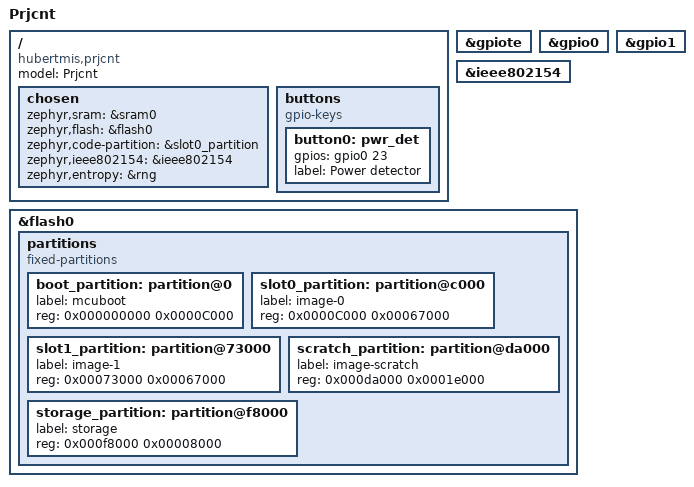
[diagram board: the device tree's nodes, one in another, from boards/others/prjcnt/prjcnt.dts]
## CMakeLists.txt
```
# Find Zephyr. This also loads Zephyr's build system.
cmake_minimum_required(VERSION 3.13.1)

set(CONF_FILE "prj.conf")
list(APPEND CONF_FILE "../config/openthread.conf")
list(APPEND CONF_FILE "../config/coap.conf")
list(APPEND CONF_FILE "../config/fota.conf")
list(APPEND CONF_FILE "../config/dfu.conf")

list(APPEND BOARD_ROOT ${CMAKE_CURRENT_SOURCE_DIR})
find_package(Zephyr REQUIRED HINTS $ENV{ZEPHYR_BASE})
project(rgbw)

# Add your source file to the "app" target. This must come after
# find_package(Zephyr) which defines the target.
target_sources(app PRIVATE src/coap.c)
target_sources(app PRIVATE src/main.c)
target_sources(app PRIVATE src/notification.c)
target_sources(app PRIVATE src/prov.c)
target_sources(app PRIVATE src/pwr_det.c)

# TODO: Replace with library target
target_include_directories(app PRIVATE ../lib)
target_sources(app PRIVATE ../lib/cbor_utils.c)
target_sources(app PRIVATE ../lib/coap_fota.c)
target_sources(app PRIVATE ../lib/coap_sd.c)
target_sources(app PRIVATE ../lib/coap_server.c)
target_sources(app PRIVATE ../lib/continuous_sd.c)
target_sources(app PRIVATE ../lib/ot_sed.c)

zephyr_get(COAPS_PSK SYSBUILD GLOBAL)
if(COAPS_PSK)
    target_compile_definitions(app PRIVATE
        -DCOAPS_PSK=${COAPS_PSK}
        )
else()
    message(FATAL_ERROR "Missing COAPS_PSK")
endif()
```

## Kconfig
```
# SPDX-License-Identifier: Apache-2.0

mainmenu "Temperature touchscreen menu"

source "Kconfig.zephyr"

config PRJCNT_NUM_NTF_SINKS
  int "prjcnt notification sinks number"
  default 6
  help
    Number of notification sinks for the projector controller application

config COAP_SD_MAX_NUM_RSRCS
  int "CoAP SD max resources"
  default PRJCNT_NUM_NTF_SINKS
  help
    Number of resources simultaneously being discovered by CoAP SD library

config CONTINUOUS_SD_MAX_NUM_RSRCS
  int "Continuous SD max resources"
  default PRJCNT_NUM_NTF_SINKS
  help
    Number of resources simultaneously being tracked by continuous SD library
```

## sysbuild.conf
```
SB_CONFIG_BOOTLOADER_MCUBOOT=y
SB_CONFIG_BOOT_SIGNATURE_TYPE_ECDSA_P256=y
```

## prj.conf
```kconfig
CONFIG_NEWLIB_LIBC=y
CONFIG_FPU=y
CONFIG_FPU_SHARING=y

CONFIG_MAIN_STACK_SIZE=3072
CONFIG_HEAP_MEM_POOL_SIZE=2048

CONFIG_FLASH=y

CONFIG_OPENTHREAD_MTD=y
CONFIG_OPENTHREAD_MTD_SED=y

CONFIG_MCUBOOT_IMGTOOL_SIGN_VERSION="0.2.0+0"

CONFIG_PRJCNT_NUM_NTF_SINKS=5
CONFIG_POSIX_MAX_FDS=16
CONFIG_NET_MAX_CONTEXTS=16
CONFIG_NET_MAX_CONN=16

CONFIG_RESET_ON_FATAL_ERROR=n
```

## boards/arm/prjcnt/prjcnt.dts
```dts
/*
 * Copyright (c) 2022 Hubert Miś
 *
 * SPDX-License-Identifier: Apache-2.0
 */

/dts-v1/;
#include <nordic/nrf52840_qiaa.dtsi>

/ {
	model = "Prjcnt";
	compatible = "hubertmis,prjcnt";

	chosen {
		zephyr,sram = &sram0;
		zephyr,flash = &flash0;
		zephyr,code-partition = &slot0_partition;
	};

    buttons {
        compatible = "gpio-keys";
        button0: pwr_det {
            gpios = <&gpio0 23 (GPIO_ACTIVE_HIGH)>;
            label = "Power detector";
        };
    };

    /*
    * In some default configurations within the nRF Connect SDK,
    * e.g. on nRF52840, the chosen zephyr,entropy node is &cryptocell.
    * This devicetree overlay ensures that default is overridden wherever it
    * is set, as this application uses the RNG node for entropy exclusively.
    */
    chosen {
        zephyr,entropy = &rng;
    };
};

&gpiote {
	status = "okay";
};

&gpio0 {
	status = "okay";
};

&gpio1 {
	status = "okay";
};

&flash0 {

	partitions {
		compatible = "fixed-partitions";
		#address-cells = <1>;
		#size-cells = <1>;

		boot_partition: partition@0 {
			label = "mcuboot";
			reg = <0x000000000 0x0000C000>;
		};
		slot0_partition: partition@c000 {
			label = "image-0";
			reg = <0x0000C000 0x00067000>;
		};
		slot1_partition: partition@73000 {
			label = "image-1";
			reg = <0x00073000 0x00067000>;
		};
		scratch_partition: partition@da000 {
			label = "image-scratch";
			reg = <0x000da000 0x0001e000>;
		};

		/*
		 * The flash starting at 0x000f8000 and ending at
		 * 0x000fffff is reserved for use by the application.
		 */

		/*
		 * Storage partition will be used by FCB/LittleFS/NVS
		 * if enabled.
		 */
		storage_partition: partition@f8000 {
			label = "storage";
			reg = <0x000f8000 0x00008000>;
		};
	};
};
```

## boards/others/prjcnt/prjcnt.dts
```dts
/*
 * Copyright (c) 2022 Hubert Miś
 *
 * SPDX-License-Identifier: Apache-2.0
 */

/dts-v1/;
#include <nordic/nrf52840_qiaa.dtsi>

/ {
	model = "Prjcnt";
	compatible = "hubertmis,prjcnt";

	chosen {
		zephyr,sram = &sram0;
		zephyr,flash = &flash0;
		zephyr,code-partition = &slot0_partition;
		zephyr,ieee802154 = &ieee802154;
	};

    buttons {
        compatible = "gpio-keys";
        button0: pwr_det {
            gpios = <&gpio0 23 (GPIO_ACTIVE_HIGH)>;
            label = "Power detector";
        };
    };

    /*
    * In some default configurations within the nRF Connect SDK,
    * e.g. on nRF52840, the chosen zephyr,entropy node is &cryptocell.
    * This devicetree overlay ensures that default is overridden wherever it
    * is set, as this application uses the RNG node for entropy exclusively.
    */
    chosen {
        zephyr,entropy = &rng;
    };
};

&gpiote {
	status = "okay";
};

&gpio0 {
	status = "okay";
};

&gpio1 {
	status = "okay";
};

&ieee802154 {
	status = "okay";
};

&flash0 {

	partitions {
		compatible = "fixed-partitions";
		#address-cells = <1>;
		#size-cells = <1>;

		boot_partition: partition@0 {
			label = "mcuboot";
			reg = <0x000000000 0x0000C000>;
		};
		slot0_partition: partition@c000 {
			label = "image-0";
			reg = <0x0000C000 0x00067000>;
		};
		slot1_partition: partition@73000 {
			label = "image-1";
			reg = <0x00073000 0x00067000>;
		};
		scratch_partition: partition@da000 {
			label = "image-scratch";
			reg = <0x000da000 0x0001e000>;
		};

		/*
		 * The flash starting at 0x000f8000 and ending at
		 * 0x000fffff is reserved for use by the application.
		 */

		/*
		 * Storage partition will be used by FCB/LittleFS/NVS
		 * if enabled.
		 */
		storage_partition: partition@f8000 {
			label = "storage";
			reg = <0x000f8000 0x00008000>;
		};
	};
};
```

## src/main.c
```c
/*
 * Copyright (c) 2021 Hubert Miś
 *
 * SPDX-License-Identifier: Apache-2.0
 */

#include <assert.h>
#include <stdbool.h>

#include <zephyr/kernel.h> // Needed by k_sleep

#include <net/fota_download.h>
#include <openthread/thread.h>
#include <zephyr/dfu/mcuboot.h>
#include <zephyr/net/openthread.h>
#include <zephyr/settings/settings.h>

#include <coap_fota.h>
#include <ot_sed.h>

#include "coap.h"
#include "notification.h"
#include "prov.h"
#include "pwr_det.h"

#define TX_POWER 8


void fota_cb(const struct coap_fota_evt *evt)
{
	switch (evt->evt) {
		case COAP_FOTA_EVT_STARTED:
			notification_pause();
			break;

		case COAP_FOTA_EVT_FINISHED:
			notification_resume();
			break;
	}
}

int main(void)
{
    notification_init();
    prov_init();

    settings_subsys_init();
    settings_register(prov_get_settings_handler());
    settings_load();

    otError error;
    struct otInstance *ot_instance = openthread_get_default_instance();

    error = otPlatRadioSetTransmitPower(ot_instance, TX_POWER);
    assert(error == OT_ERROR_NONE);

    struct otIp6Address site_local_all_nodes_addr = {.mFields = {.m8 =
            {0xff, 0x05, 0x00, 0x00, 0x00, 0x00, 0x00, 0x00,
             0x00, 0x00, 0x00, 0x00, 0x00, 0x00, 0x00, 0x01} }};

    error = otIp6SubscribeMulticastAddress(ot_instance, &site_local_all_nodes_addr);
    assert(error == OT_ERROR_NONE);

    ot_sed_init(ot_instance);
    fota_download_init(coap_fota_callback);
    coap_fota_register_cb(fota_cb);
    coap_init();
    pwr_det_init();

    boot_write_img_confirmed();

    return 0;
}
```

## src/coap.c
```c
/*
 * Copyright (c) 2021 Hubert Miś
 *
 * SPDX-License-Identifier: Apache-2.0
 */

#include "coap.h"

#include <errno.h>
#include <stdbool.h>
#include <stdint.h>
#include <stdio.h>

#include <cbor_utils.h>
#include <coap_fota.h>
#include <coap_sd.h>
#include <coap_server.h>
#include "prov.h"

#include <net/fota_download.h>
#include <zcbor_decode.h>
#include <zcbor_encode.h>
#include <zephyr/net/socket.h>
#include <zephyr/net/coap.h>
#include <zephyr/net/tls_credentials.h>

#define MAX_COAP_MSG_LEN 256
#define MAX_COAP_PAYLOAD_LEN 64

#define MANUAL_VALIDITY_MS (10UL * 3600UL * 1000UL)

#define RSRC_KEY "r"
#define OUT_KEY "o"
#define OUT_KEY_MAX_LEN (sizeof(OUT_KEY) + 2)

static int get_out_key(char *out_buffer, size_t size, int id)
{
	return snprintf(out_buffer, size, "%s%d", OUT_KEY, id);
}

static int handle_prov_post(zcbor_state_t *cd,
	       	enum coap_response_code *rsp_code, void *context)
{
    (void)context;

    bool updated = false;
    int r;
    char str[PROV_LBL_MAX_LEN];

    // Handle rsrc
    r = cbor_extract_from_map_string(cd, RSRC_KEY, str, sizeof(str));
    if ((r >= 0) && (r < PROV_LBL_MAX_LEN)) {
        r = prov_set_rsrc_label(str);

        if (r == 0) {
            updated = true;
        }
    }

    // Handle outs
    for (int i = 0; i < CONFIG_PRJCNT_NUM_NTF_SINKS; i++) {
        char key[OUT_KEY_MAX_LEN];
        r = get_out_key(key, sizeof(key), i);
        if ((r < 0) || (r >= sizeof(key))) {
            *rsp_code = COAP_RESPONSE_CODE_INTERNAL_ERROR;
            return -EINVAL;
        }

        r = cbor_extract_from_map_string(cd, key, str, sizeof(str));
        if ((r >= 0) && (r < PROV_LBL_MAX_LEN)) {
            r = prov_set_out_label(i, str);

            if (r == 0) {
                updated = true;
            }
        }
    }

    if (updated) {
        *rsp_code = COAP_RESPONSE_CODE_CHANGED;
        prov_store();
    }

    return r;
}

static int prov_post(struct coap_resource *resource,
        struct coap_packet *request,
        struct sockaddr *addr, socklen_t addr_len)
{
    int sock = *(int*)resource->user_data;

    return coap_server_handle_simple_setter(sock, resource, request, addr, addr_len,
		    handle_prov_post, NULL);
}

static int prepare_prov_payload(uint8_t *payload, size_t len)
{
    ZCBOR_STATE_E(ce, 2, payload, len, 1);
    const char *label;
    int r;


    if (!zcbor_map_start_encode(ce, 1 + CONFIG_PRJCNT_NUM_NTF_SINKS)) return -EINVAL;

    label = prov_get_rsrc_label();
    if (!zcbor_tstr_put_lit(ce, RSRC_KEY)) return -EINVAL;
    if (!zcbor_tstr_put_term(ce, label, 8)) return -EINVAL;

    for (int i = 0; i < CONFIG_PRJCNT_NUM_NTF_SINKS; i++) {
        char key[OUT_KEY_MAX_LEN];
        r = get_out_key(key, sizeof(key), i);
        if ((r < 0) || (r >= sizeof(key))) {
            return -EINVAL;
        }

        label = prov_get_out_label(i);
        if (label == NULL) {
            return -EINVAL;
        }

        if (!zcbor_tstr_put_term(ce, key, 8)) return -EINVAL;
        if (!zcbor_tstr_put_term(ce, label, 8)) return -EINVAL;
    }

    if (!zcbor_map_end_encode(ce, 1 + CONFIG_PRJCNT_NUM_NTF_SINKS)) return -EINVAL;

    return (size_t)(ce->payload - payload);
}

static int prov_get(struct coap_resource *resource,
        struct coap_packet *request,
        struct sockaddr *addr, socklen_t addr_len)
{
    int sock = *(int*)resource->user_data;
    int r = 0;
    uint8_t payload[MAX_COAP_PAYLOAD_LEN];
    size_t payload_len;

    r = prepare_prov_payload(payload, MAX_COAP_PAYLOAD_LEN);
    if (r < 0) {
        return r;
    }
    payload_len = r;

    r = coap_server_handle_simple_getter(sock, resource, request, addr, addr_len,
                    payload, payload_len);

    return r;
}

#if 0
#define RED_KEY "r"
#define GREEN_KEY "g"
#define BLUE_KEY "b"
#define WHITE_KEY "w"
#define DUR_KEY "d"
#define PRESET_KEY "p"
#define RESET_KEY "res"

static int handle_color(zcbor_state_t *cd, const char *key, unsigned *color_val)
{
    int new_color;
    int ret = cbor_extract_from_map_int(cd, key, &new_color);

    if (!ret) {
        if ((new_color <= MAX_BRIGHTNESS) && (new_color >= 0)) {
            *color_val = new_color;
            return 0;
        } else {
            return -EINVAL;
        }
    }

    return ret;
}

static int handle_rsrc_post(zcbor_state_t *cd, enum coap_response_code *rsp_code, void *context)
{
    bool updated = false;
    int ret;
    struct leds_brightness leds;
    unsigned dur = 0;
    int new_dur, p;
    bool reset = false;

    if (led_get(&leds) != 0) {
        *rsp_code = COAP_RESPONSE_CODE_INTERNAL_ERROR;
        return -EINVAL;
    }

    *rsp_code = COAP_RESPONSE_CODE_BAD_REQUEST;

    // Handle red
    ret = handle_color(cd, RED_KEY, &leds.r);
    if (!ret) {
        updated = true;
    }

    // Handle green
    ret = handle_color(cd, GREEN_KEY, &leds.g);
    if (!ret) {
        updated = true;
    }

    // Handle blue
    ret = handle_color(cd, BLUE_KEY, &leds.b);
    if (!ret) {
        updated = true;
    }

    // Handle white
    ret = handle_color(cd, WHITE_KEY, &leds.w);
    if (!ret) {
        updated = true;
    }

    // Handle duration
    ret = cbor_extract_from_map_int(cd, DUR_KEY, &new_dur);
    if (!ret) {
        dur = new_dur;
    }

    // Handle preset
    ret = cbor_extract_from_map_int(cd, PRESET_KEY, &p);
    if (!ret) {
        ret = preset_get(p, &leds, &dur);
        if (!ret) {
            updated = true;
        }
    }

    // Handle reset
    ret = cbor_extract_from_map_bool(cd, RESET_KEY, &reset);
    if (!ret && reset) {
        *rsp_code = COAP_RESPONSE_CODE_CHANGED;
        led_ctlr_reset_manual();
        updated = false;
    }

    if (updated) {
        *rsp_code = COAP_RESPONSE_CODE_CHANGED;
        led_ctlr_set_manual(&leds, dur, MANUAL_VALIDITY_MS);
    }

    return ret;
}

static int rsrc_post(struct coap_resource *resource,
        struct coap_packet *request,
        struct sockaddr *addr, socklen_t addr_len)
{
    int sock = *(int*)resource->user_data;

    return coap_server_handle_simple_setter(sock, resource, request, addr, addr_len,
		    handle_rgbw_post, NULL);
}


static int prepare_rsrc_payload(uint8_t *payload, size_t len)
{
    ZCBOR_STATE_E(ce, 2, payload, len, 1);
    struct leds_brightness leds;

    if (led_get(&leds) != 0) return -EINVAL;

    if (!zcbor_map_start_encode(ce, 4)) return -EINVAL;

    if (!zcbor_tstr_put_lit(ce, RED_KEY)) return -EINVAL;
    if (!zcbor_int32_put(ce, leds.r)) return -EINVAL;

    if (!zcbor_tstr_put_lit(ce, GREEN_KEY)) return -EINVAL;
    if (!zcbor_int32_put(ce, leds.g)) return -EINVAL;

    if (!zcbor_tstr_put_lit(ce, BLUE_KEY)) return -EINVAL;
    if (!zcbor_int32_put(ce, leds.b)) return -EINVAL;

    if (!zcbor_tstr_put_lit(ce, WHITE_KEY)) return -EINVAL;
    if (!zcbor_int32_put(ce, leds.w)) return -EINVAL;

    if (!zcbor_map_end_encode(ce, 4)) return -EINVAL;

    return (size_t)(ce->payload - payload);
}

static int rsrc_get(struct coap_resource *resource,
        struct coap_packet *request,
        struct sockaddr *addr, socklen_t addr_len)
{
    int sock = *(int*)resource->user_data;
    int r = 0;
    uint8_t payload[MAX_COAP_PAYLOAD_LEN];
    size_t payload_len;

    r = prepare_rgb_payload(payload, MAX_COAP_PAYLOAD_LEN);
    if (r < 0) {
        return r;
    }
    payload_len = r;

    return coap_server_handle_simple_getter(sock, resource, request, addr, addr_len,
                    payload, payload_len);
}
#endif

static struct coap_resource * rsrcs_get(int sock)
{
    static const char * const fota_path [] = {"fota_req", NULL};
    static const char * const sd_path [] = {"sd", NULL};
    static const char * const prov_path[] = {"prov", NULL};
    //static const char * rsrc_path[] = {NULL, NULL};

    static struct coap_resource resources[] = {
        { .get = coap_fota_get,
          .post = coap_fota_post,
          .path = fota_path,
        },
        { .get = coap_sd_server,
          .path = sd_path,
        },
        { .get = prov_get,
          .post = prov_post,
          .path = prov_path,
        },
#if 0
        { .get = rsrc_get,
          .post = rsrc_post,
          .path = rsrc_path,
        },
#endif
        { .path = NULL } // Array terminator
    };

#if 0
    rsrc_path[0] = prov_get_rsrc_label();

    if (!rsrc_path[0] || !strlen(rsrc_path[0])) {
	    resources[ARRAY_SIZE(resources)-2].path = NULL;
    } else {
	    resources[ARRAY_SIZE(resources)-2].path = rsrc_path;
    }
#endif

    // TODO: Replace it with something better
    static int user_data;

    user_data = sock;

    for (int i = 0; i < ARRAY_SIZE(resources); ++i) {
        resources[i].user_data = &user_data;
    }

    return resources;
}

void coap_init(void)
{
    coap_server_init(rsrcs_get);
}
```

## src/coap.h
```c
/*
 * Copyright (c) 2020 Hubert Miś
 *
 * SPDX-License-Identifier: Apache-2.0
 */

/**
 * @file
 * @brief CoAP Server
 */
    
#ifndef COAP_H_
#define COAP_H_

#ifdef __cplusplus
extern "C" {
#endif

void coap_init(void);

#ifdef __cplusplus
}   
#endif

#endif // COAP_H_
```

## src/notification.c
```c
/*
 * Copyright (c) 2022 Hubert Miś
 *
 * SPDX-License-Identifier: Apache-2.0
 */

#include "notification.h"

#include <zcbor_encode.h>
#include <zephyr/kernel.h>
#include <zephyr/net/coap.h>
#include <zephyr/net/socket.h>

#include <continuous_sd.h>

#define COAP_PORT 5683
#define MAX_COAP_MSG_LEN 256
#define MAX_COAP_PAYLOAD_LEN 64

#define PRJ_ENABLED_URI_PATH "prj"
#define PRJ_ENABLED_KEY "p"

#define NTF_INTERVAL (15 * 1000)
#define NTF_TARGETS_NUM CONFIG_PRJCNT_NUM_NTF_SINKS
static const char *ntf_targets[NTF_TARGETS_NUM];

K_SEM_DEFINE(ntf_out_sem, 0, 1);

#define OUT_THREAD_STACK_SIZE 2048
#define OUT_THREAD_PRIO       0
static void out_thread_process(void *a1, void *a2, void *a3);

K_THREAD_DEFINE(ntf_out_thread_id, OUT_THREAD_STACK_SIZE,
                out_thread_process, NULL, NULL, NULL,
                OUT_THREAD_PRIO, K_ESSENTIAL, K_TICKS_FOREVER);

static bool paused = false;
static bool prj_enabled = true;

static int prepare_req_payload(uint8_t *payload, size_t len, bool enabled)
{
    ZCBOR_STATE_E(state, 2, payload, len, 1);

    if (!zcbor_map_start_encode(state, 1)) return -EINVAL;
    if (!zcbor_tstr_put_lit(state, PRJ_ENABLED_KEY)) return -EINVAL;
    if (!zcbor_bool_put(state, enabled)) return -EINVAL;
    if (!zcbor_map_end_encode(state, 1)) return -EINVAL;

    return (size_t)(state->payload - payload);
}

static int send_req(int sock, struct sockaddr_in6 *addr, const char *rsrc, bool prj_enabled)
{
    int r;
    struct coap_packet cpkt;
    uint8_t *data;
    uint8_t payload[MAX_COAP_PAYLOAD_LEN];

    data = (uint8_t *)k_malloc(MAX_COAP_MSG_LEN);
    if (!data) {
        return -ENOMEM;
    }

    r = coap_packet_init(&cpkt, data, MAX_COAP_MSG_LEN,
                 1, COAP_TYPE_NON_CON, 4, coap_next_token(),
                 COAP_METHOD_POST, coap_next_id());
    if (r < 0) {
        goto end;
    }

    r = coap_packet_append_option(&cpkt, COAP_OPTION_URI_PATH, rsrc, strlen(rsrc));
    if (r < 0) {
        goto end;
    }

    r = coap_packet_append_option(&cpkt, COAP_OPTION_URI_PATH, PRJ_ENABLED_URI_PATH, strlen(PRJ_ENABLED_URI_PATH));
    if (r < 0) {
        goto end;
    }

    r = coap_append_option_int(&cpkt, COAP_OPTION_CONTENT_FORMAT,
            COAP_CONTENT_FORMAT_APP_CBOR);
    if (r < 0) {
        goto end;
    }

    r = coap_packet_append_payload_marker(&cpkt);
    if (r < 0) {
        goto end;
    }

    r = prepare_req_payload(payload, MAX_COAP_PAYLOAD_LEN, prj_enabled);
    if (r < 0) {
        goto end;
    }

    r = coap_packet_append_payload(&cpkt, payload, r);
    if (r < 0) {
        goto end;
    }

    r = sendto(sock, cpkt.data, cpkt.offset, 0, (struct sockaddr *)addr, sizeof(*addr));
    if (r < 0) {
        r = -errno;
        goto end;
    }

end:
    k_free(data);

    return r;
}

static void out_thread_process(void *a1, void *a2, void *a3)
{
    (void)a1;
    (void)a2;
    (void)a3;

    // Prepare socket
    int r;
    int sock;
    struct sockaddr_in6 rmt_addr = {
        .sin6_family = AF_INET6,
        .sin6_port = htons(COAP_PORT),
    };
    struct in6_addr *addr = &rmt_addr.sin6_addr;

    sock = socket(AF_INET6, SOCK_DGRAM, IPPROTO_UDP);
    if (sock < 0) {
        return;
    }

    while (1) {
        k_sem_take(&ntf_out_sem, K_MSEC(NTF_INTERVAL));

        if (paused) {
            continue;
        }

        // TODO: Mutex when using discovered_addr?
        for (int i = 0; i < NTF_TARGETS_NUM; i++)
        {
            const char *out_label = ntf_targets[i];
            if (out_label == NULL) continue;

            r = continuous_sd_get_addr(out_label, NULL, addr);
            if (r) continue; // TODO: Try faster?

            if (!net_ipv6_is_addr_unspecified(addr))
            {
       	        send_req(sock, &rmt_addr, out_label, prj_enabled);
            }
        }
    }

    close(sock);
}

void notification_init(void)
{
	for (int i = 0; i < NTF_TARGETS_NUM; i++)
	{
		ntf_targets[i] = NULL;
	}

	k_thread_start(ntf_out_thread_id);
}

void notification_reset_targets(void)
{
	for (int i = 0; i < NTF_TARGETS_NUM; i++)
	{
		ntf_targets[i] = NULL;
	}

	continuous_sd_unregister_all();
}

int notification_add_target(const char *name)
{
	int r;

	for (int i = 0; i < NTF_TARGETS_NUM; i++)
	{
		if (ntf_targets[i] != NULL) continue;
		r = continuous_sd_register(name, NULL, false);

		if (!r) {
			ntf_targets[i] = name;
		}

		return r;
	}

	return -ENOMEM;
}

void notification_set_prj_state(bool enabled)
{
	prj_enabled = enabled;
	k_sem_give(&ntf_out_sem);
}

int notification_pause(void)
{
	paused = true;

	return 0;
}

int notification_resume(void)
{
	paused = false;

	return 0;
}
```

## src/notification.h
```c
/*
 * Copyright (c) 2022 Hubert Miś
 *
 * SPDX-License-Identifier: Apache-2.0
 */

/**
 * @file
 * @brief Projector state remote notification
 */
    
#ifndef NOTIFICATION_H_
#define NOTIFICATION_H_

#ifdef __cplusplus
extern "C" {
#endif

#include <stdbool.h>

void notification_init(void);
void notification_reset_targets(void);
int notification_add_target(const char *name);
void notification_set_prj_state(bool enabled);

int notification_pause(void);
int notification_resume(void);

#ifdef __cplusplus
}   
#endif

#endif // NOTIFICATION_H_
```

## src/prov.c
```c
/*
 * Copyright (c) 2021 Hubert Miś
 *
 * SPDX-License-Identifier: Apache-2.0
 */

#include "prov.h"

#include <errno.h>
#include <stdio.h>
#include <string.h>
#include <zephyr/settings/settings.h>

#include <coap_sd.h>
#include "notification.h"

#define SETT_NAME "prov"
#define RSRC_NAME "r"
#define OUT_NAME "o"
#define RSRC_TYPE "prj"

#define OUT_NAME_MAX_LEN (sizeof(OUT_NAME) + 2)

static char rsrc_label[PROV_LBL_MAX_LEN];
static const char rsrc_type[] = RSRC_TYPE;

static char out_labels[PROV_NUM_OUTS][PROV_LBL_MAX_LEN];

static int get_out_name(char *out_name, size_t size, int id)
{
	return snprintf(out_name, size, "%s%d", OUT_NAME, id);
}

void prov_init(void)
{
    rsrc_label[0] = '\0';
}

int prov_set_rsrc_label(const char *new_rsrc_label)
{
    if (strlen(new_rsrc_label) >= PROV_LBL_MAX_LEN) {
        return -2;
    }

    strncpy(rsrc_label, new_rsrc_label, PROV_LBL_MAX_LEN);
    return 0;
}

const char *prov_get_rsrc_label(void)
{
    return rsrc_label;
}

int prov_set_out_label(int id, const char *new_out_label)
{
	if (id < 0 || id >= PROV_NUM_OUTS) {
		return -1;
	}
	if (strlen(new_out_label) >= PROV_LBL_MAX_LEN) {
		return -2;
	}

	strncpy(out_labels[id], new_out_label, PROV_LBL_MAX_LEN);
	return 0;
}

const char *prov_get_out_label(int id)
{
	if (id < 0 || id >= PROV_NUM_OUTS) {
		return NULL;
	}

	return out_labels[id];
}

static int set_out_from_nvm(int id, size_t len, settings_read_cb read_cb, void *cb_arg)
{
	int rc;

	if (id < 0 || id >= PROV_NUM_OUTS) {
		return -EINVAL;
	}
	if (len >= PROV_LBL_MAX_LEN) {
		return -EINVAL;
	}

	rc = read_cb(cb_arg, out_labels[id], PROV_LBL_MAX_LEN);

	if (rc < 0) {
		return rc;
	}

	out_labels[id][rc] = '\0';
	notification_add_target(out_labels[id]);

	return 0;
}

static int prov_set_from_nvm(const char *name, size_t len,
                             settings_read_cb read_cb, void *cb_arg)
{
    const char *next;
    int rc;

    if (settings_name_steq(name, RSRC_NAME, &next) && !next) {
        if (len >= PROV_LBL_MAX_LEN) {
            return -EINVAL;
        }

        rc = read_cb(cb_arg, rsrc_label, PROV_LBL_MAX_LEN);

        if (rc < 0) {
            return rc;
        }

        rsrc_label[rc] = '\0';
	coap_sd_server_register_rsrc(rsrc_label, rsrc_type);

        return 0;
    }

    for (int i = 0; i < PROV_NUM_OUTS; i++) {
        char out_label[OUT_NAME_MAX_LEN];
        rc = get_out_name(out_label, sizeof(out_label), i);
	if ((rc < 0) || (rc >= sizeof(out_label))) {
		continue;
	}

        if (settings_name_steq(name, out_label, &next) && !next) {
            return set_out_from_nvm(i, len, read_cb, cb_arg);
        }
    }

    return -ENOENT;
}

static struct settings_handler sett_conf = {
    .name = SETT_NAME,
    .h_set = prov_set_from_nvm,
};

void prov_store(void)
{
	settings_save_one(SETT_NAME "/" RSRC_NAME, rsrc_label, strlen(rsrc_label));
        for (int i = 0; i < PROV_NUM_OUTS; i++) {
            int r;
            char out_label[OUT_NAME_MAX_LEN];
	    char sett_label[sizeof(SETT_NAME) + 1 + OUT_NAME_MAX_LEN];
            r = get_out_name(out_label, sizeof(out_label), i);
	    if ((r < 0) || (r >= sizeof(out_label))) {
		    continue;
	    }
	    r = snprintf(sett_label, sizeof(sett_label), "%s/%s", SETT_NAME, out_label);
	    if ((r < 0) || (r >= sizeof(sett_label))) {
		    continue;
	    }
            settings_save_one(sett_label, out_labels[i], strlen(out_labels[i]));

		if (strlen(out_labels[i])) {
			notification_add_target(out_labels[i]);
		}
        }
	coap_sd_server_clear_all_rsrcs();
	coap_sd_server_register_rsrc(rsrc_label, rsrc_type);

	notification_reset_targets();
	for (int i = 0; i < PROV_NUM_OUTS; i++) {
		if (strlen(out_labels[i])) {
			notification_add_target(out_labels[i]);
		}
	}
}

struct settings_handler *prov_get_settings_handler(void)
{
    return &sett_conf;
}
```

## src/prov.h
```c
/*
 * Copyright (c) 2021 Hubert Miś
 *
 * SPDX-License-Identifier: Apache-2.0
 */

/**
 * @file
 * @brief Provisioning settings
 */
    
#ifndef PROV_H_
#define PROV_H_

#ifdef __cplusplus
extern "C" {
#endif

#define PROV_LBL_MAX_LEN 6
#define PROV_NUM_OUTS CONFIG_PRJCNT_NUM_NTF_SINKS

void prov_init(void);
int prov_set_rsrc_label(const char *rsrc_label);
const char *prov_get_rsrc_label(void);
int prov_set_out_label(int id, const char *out_label);
const char *prov_get_out_label(int id);
void prov_store(void);
struct settings_handler *prov_get_settings_handler(void);

#ifdef __cplusplus
}   
#endif

#endif // PROV_H_
```

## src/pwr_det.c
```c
/*
 * Copyright (c) 2022 Hubert Miś
 *
 * SPDX-License-Identifier: Apache-2.0
 */

#include "pwr_det.h"

#include <zephyr/device.h>
#include <zephyr/drivers/gpio.h>

#include "notification.h"

#define SW0_NODE	DT_NODELABEL(button0)
#if !DT_NODE_HAS_STATUS(SW0_NODE, okay)
#error "Unsupported board: button0 devicetree node label is not defined"
#endif
static const struct gpio_dt_spec button = GPIO_DT_SPEC_GET_OR(SW0_NODE, gpios,
							      {0});
static struct gpio_callback button_cb_data;

static void button_pressed(const struct device *dev, struct gpio_callback *cb,
		    uint32_t pins)
{
	(void)dev;
	(void)cb;
	(void)pins;

	int val = gpio_pin_get_dt(&button);
	bool prj_state = val > 0;

	notification_set_prj_state(prj_state);
}

static void init_gpio(void)
{
	int ret;

	if (!device_is_ready(button.port)) {
		return;
	}

	ret = gpio_pin_configure_dt(&button, GPIO_INPUT);
	if (ret != 0) {
		return;
	}

	ret = gpio_pin_interrupt_configure_dt(&button, GPIO_INT_EDGE_BOTH);
	if (ret != 0) {
		return;
	}

	gpio_init_callback(&button_cb_data, button_pressed, BIT(button.pin));
	gpio_add_callback(button.port, &button_cb_data);

	button_pressed(NULL, NULL, 0);
}

void pwr_det_init(void)
{
	init_gpio();
}
```

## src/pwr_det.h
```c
/*
 * Copyright (c) 2022 Hubert Miś
 *
 * SPDX-License-Identifier: Apache-2.0
 */

/**
 * @file
 * @brief Detection if the board is powered
 */
    
#ifndef PWR_DET_H_
#define PWR_DET_H_

#ifdef __cplusplus
extern "C" {
#endif

void pwr_det_init(void);

#ifdef __cplusplus
}   
#endif

#endif // PWR_DET_H_
```
